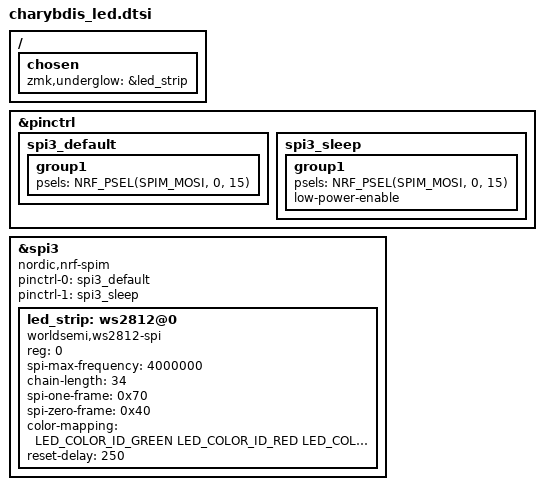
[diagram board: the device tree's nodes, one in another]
/*
 * Copyright (c) 2024 The ZMK Contributors
 * SPDX-License-Identifier: MIT
 *
 * Charybdis LED configuration for SK6812 MINI-E addressable RGB LEDs
 * Uses SPI3 MOSI on P0.15 (D2) on nice!nano v2 - available on both halves
 * SK6812 MINI-E: reverse-mount 3528 package, GRB color order, 800kHz protocol
 */

#include <dt-bindings/led/led.h>
#include <dt-bindings/pinctrl/nrf-pinctrl.h>

&pinctrl {
    spi3_default: spi3_default {
        group1 {
            psels = <NRF_PSEL(SPIM_MOSI, 0, 15)>;
        };
    };

    spi3_sleep: spi3_sleep {
        group1 {
            psels = <NRF_PSEL(SPIM_MOSI, 0, 15)>;
            low-power-enable;
        };
    };
};

&spi3 {
    compatible = "nordic,nrf-spim";
    status = "okay";

    pinctrl-0 = <&spi3_default>;
    pinctrl-1 = <&spi3_sleep>;
    pinctrl-names = "default", "sleep";

    led_strip: ws2812@0 {
        compatible = "worldsemi,ws2812-spi";

        /* SPI configuration */
        reg = <0>;
        spi-max-frequency = <4000000>;

        /* SK6812 MINI-E LED strip */
        chain-length = <34>;
        spi-one-frame = <0x70>;
        spi-zero-frame = <0x40>;
        color-mapping = <LED_COLOR_ID_GREEN LED_COLOR_ID_RED LED_COLOR_ID_BLUE>;
        reset-delay = <250>;
    };
};

/ {
    chosen {
        zmk,underglow = &led_strip;
    };
};
